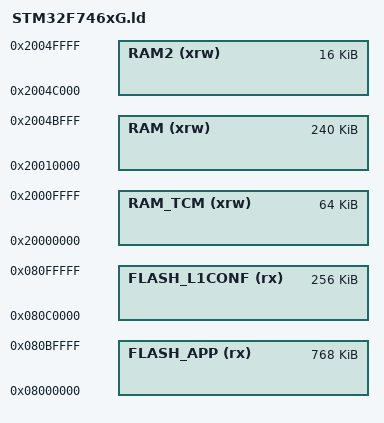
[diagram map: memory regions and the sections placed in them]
/* CPU: STM32F745xG */

/*
Extra RAM for real time data:
TCM_RAM (xrw)  : ORIGIN = XXXXXXXXXX, LENGTH = 32K
*/

MEMORY
{
RAM_TCM (xrw)     : ORIGIN = 0x20000000, LENGTH = 64K
RAM (xrw)         : ORIGIN = 0x20010000, LENGTH = 240K
RAM2 (xrw)        : ORIGIN = 0x2004c000, LENGTH = 16K
FLASH_APP (rx)    : ORIGIN = 0x08000000, LENGTH = 1024K - 256K
FLASH_L1CONF (rx) : ORIGIN = 0x080c0000, LENGTH = 256K
}

INCLUDE "STM32.ld"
